# soc_debugss_secure register map
Vendor: Texas Instruments
Peripheral module from a debugger description file (folder CC35X1E).
Registers are 32-bit, read-only, reset 0x0 unless marked. A register's access mark holds for its fields unless they carry their own. Offsets are as the file gives them; lines under a group give offsets from that group; [hi:lo] are bit positions; {n}, {i} and the like mark numbered series; 'fields as' and 'values as' point back to an identical list; <NAME> marks a mode.

## soc_debugss_secure
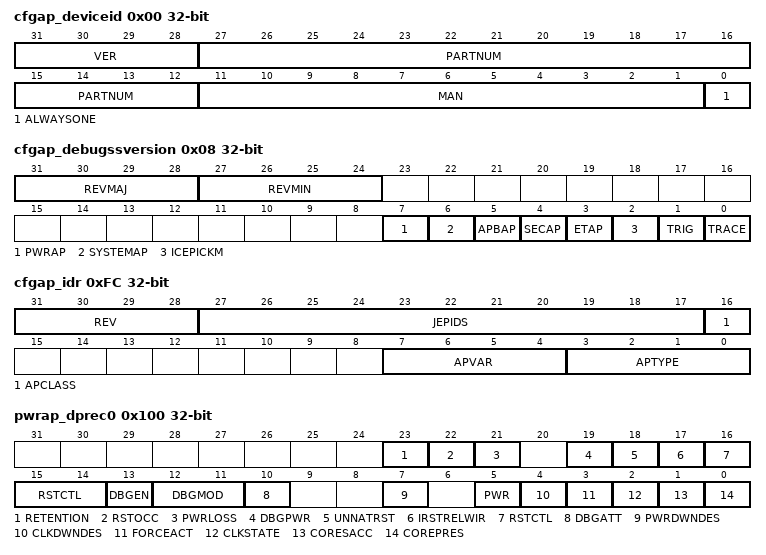
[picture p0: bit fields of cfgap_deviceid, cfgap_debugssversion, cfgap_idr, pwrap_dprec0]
0x00 cfgap_deviceid reset not defined — CFGAP Device ID. The device identification register allows the manufacturer, part number, and version of a component to be determined. This is the same 32-bit value obtained via the IDCODE instruction in the optional ICEPickM Scan module and is determined by tie-offs at DebugSS boundary.
  [31:28] VER — Revision of the device. This field should change each time that the logic or mask set of the device is revised.
  [27:12] PARTNUM — Identifies the part
  [11:1] MAN — TI's JEDEC bank and company code, which is 00000010111b
  [0] ALWAYSONE — The value 1 in bit 0 of a JTAG IDCODE means that a 32-bit scan register exists. This is replicated here for completeness.
0x04 cfgap_deviceusercode — CFGAP Device User Code. The Device Usercode register is used in conjunction with the Device Identification Register to provide extended device information. This is the same 32-bit value obtained via the USERCODE instruction in the optional ICEPickM Scan module and is determined by tie-offs at DebugSS boundary.
  [31:0] USERCODE — The Device Usercode register is used in conjunction with the Device Identification Register to provide extended device information. This is the same 32-bit value obtained via the USERCODE instruction in the optional ICEPickM Scan module and is determined by tie-offs at DebugSS boundary.
0x08 cfgap_debugssversion reset not defined — CFGAP DEBUGSS Version. The DebugSS Configuration Register provides information on the configuration of this particular instance of the subsystem.
  [31:28] REVMAJ — Indicates the major revision of this Subsystem instance.
  [27:24] REVMIN — Indicates the minor revision of this Subsystem instance. Currently 0000b
  [7] PWRAP — A value of '1' indicates this subsystem instance contains a Power-AP module
  [6] SYSTEMAP — A value of '1' indicates this subsystem instance contains an AHB-AP module for system bus mastering
  [5] APBAP — A value of '1' indicates this subsystem instance contains an ABP-AP for accessing system level debug components
  [4] SECAP — A value of '1' indicates this subsystem instance contains a Secure AP
  [3] ETAP — A value of '1' indicates this subsystem instance contains an EnergyTrace AP
  [2] ICEPICKM — A value of '1' indicates this subsystem instance contains an ICEPickM Scan module for extended scan support
  [1] TRIG — A value of '1' indicates this subsystem instance contains Cross Trigger submodule
  [0] TRACE — A value of '1' indicates this subsystem instance contains a Trace submodule
0x10 cfgap_bootdiag — CFGAP Boot Diag. This register provides feedback on the boot process
  [31:0] DIAGVAL — This register provides feedback on the boot process [3:0] PG_Version [5:3] Metal_Version [8:6] Memory Stacking [11:9] Package type [13:12] Temperature [17:14] Device PartNumber [18] Disable 5GHz [19] Disable 6GHz [20] Disable BLE [21] Disable BLE M0+ [22] Disable CAN FD [25:23] Boot ROM Version (FMU) [26] Launch pad Mode [28:27] SDIO Product ID [31:29] TI Fuse ROM Structure Version
0x14 cfgap_lifecyclestate — CFGAP Life-cycle. Indicates the current device lifecycle state
  [31:0] LCSVAL — Life cycle state [3:0] PG_Version [5:3] Metal_Version [8:6] Memory Stacking [11:9] Package type [13:12] Temperature [17:14] Device PartNumber [18] Disable 5GHz [19] Disable 6GHz [20] Disable BLE [21] Disable BLE M0+ [22] Disable CAN FD [25:23] Boot ROM Version (FMU) [26] Launch pad Mode [28:27] SDIO Product ID [31:29] TI Fuse ROM Structure Version
0x18 dft_en access per field — DFT Enable. This bit can be configured to enable multiplexing of JTAG signals on device pins.
  [0] EN rw — This bit can be configured to enable multiplexing of JTAG signals on device pins. Pin #2 --> TCK ;Pin #3 --> TMS ; Pin #10 --> TDI ; Pin #15 --> TDO. Refer to pinout_iomux.xls for more information.
0x1C rst_req access per field — Reset Request. This bit can be configured to request reset.
  [0] REQ wo — This bit can be configured to request device reset
0x28 cfgap_unique_deviceid_0 — CFGAP Unique Device 0. Used to provide a unique device ID/token for security authentication of tester and tools. Unique device ID is 64bit value and this register reads lower 32 bits.
  [31:0] VAL — Used to provide a unique divide ID/token for security authentication of tester and tools
0x2C cfgap_unique_deviceid_1 — CFGAP Unique Device 1. Used to provide a unique device ID/token for security authentication of tester and tools. Unique device ID is 64bit value and this register reads upper 32 bits.
  [31:0] VAL — Used to provide a unique devide ID/token for security authentication of tester and tools
0xFC cfgap_idr reset not defined — CFGAP Identification Register. AP Identification Register. The AP identification register allows tools to determine the manufacturer and the type of AP.
  [31:28] REV — Component Revision. Indicates the revision of this AP instance. Currently 0001b
  [27:17] JEPIDS — Manufacturer JEP106 ID. The concatenated JEP106 ID and continuation ID for TI. This is 00000010111b.
  [16] APCLASS — AP Class. 0 indicates that this AP is not a bridge to a memory interconnect (not a Memory Access Port).
  [7:4] APVAR — AP Variant. There is only one variant for this AP Type and it is 0.
  [3:0] APTYPE — The AP Type Register. TI Subsystem Config APs have a type of 0001b
0x100 pwrap_dprec0 access per field — Sub-Domain PREC Register This register provides an interface for debug tooling to obtain status and override the power, reset and execution state of debug targets in dynamically controlled sub-domains.
  [23] RETENTION ro — Used to indicate that the domain entered retention since the bit is cleared. Not supported in MX.
  [22] RSTOCC rw — Input from CPU-SS. Used by debug tools. A sticky bit Indicate that a reset to WSOC MCU has happened since last time tools checked. Cleared on write by the tool.
  [21] PWRLOSS rw — Input from PRCM. Used by debug tools. A sticky bit Indicate that a power loss to CORE has happened since last time tools checked. Cleared on write by the tool.
  [19] DBGPWR ro — Used to indicate power state of debug logic in the associated domain. 0 -> Debug logic is off. 1 -> Debug logic is powered.
  [18] UNNATRST ro — input from PRCM. "1" indicate that WSOC MCU (SYSRSTn) reset is extended.
  [17] IRSTRELWIR rw — Input from PRCM. "1" indicates WSOC MCU is in reset. Setting this bit shall release the extended SYSRSTn to WSOc MCU.
  [16:14] RSTCTL rw — Following are the field values with their description. 000 -> Normal Operation; 001 -> Wait in Reset (Reset Ext); 010 -> Block Reset; 100- > Reset Req.
  [13] DBGEN rw — Defines operating mode of debug logic in Cortex. Not used in MX.
  [12:11] DBGMOD rw — Used to define debug properties. Not used in MX.
  [10] DBGATT ro — Input from CPU-SS. "1" indicate that WSOC MCU is halted and in debug mode.
  [7] PWRDWNDES ro — Input from ELP. Indicates that CORE domain can be shutdown.
  [5] PWR ro — Input from PRCM. "1" indicates CORE domain is powered.
  [4] CLKDWNDES ro — "1" indicated that WSOC MCU is clocked artificially.
  [3] FORCEACT rw — Provides debug override of the default state of the CORE P.D power and clock.
  [2] CLKSTATE ro — Input from CPU-SS. "1" indicated that WSOC MCU is clocked by it's functional clock.
  [1] CORESACC ro — Input from DSSM. Indicate that WSOC MCU Power-AP overrides are writable.
  [0] COREPRES ro — 1 indicates that WSOC MCU is present in this Osprey device.
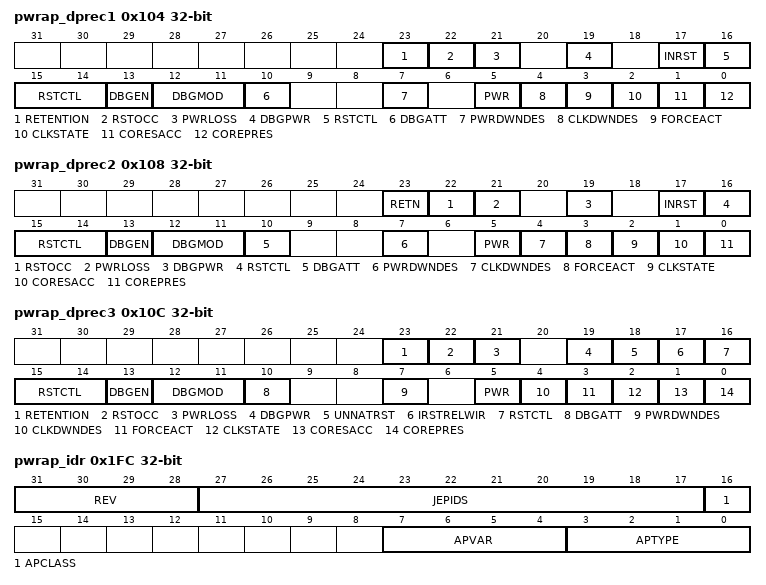
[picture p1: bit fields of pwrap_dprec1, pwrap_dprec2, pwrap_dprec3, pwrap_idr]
0x104 pwrap_dprec1 access per field — Sub-Domain PREC Register This register provides an interface for debug tooling to obtain status and override the power, reset and execution state of debug targets in dynamically controlled sub-domains.
  [23] RETENTION ro — Used to indicate that the domain entered retention since the bit is cleared. Not supported in MX.
  [22] RSTOCC rw — Input from CPU-SS. Used by debug tools. A sticky bit Indicate that a reset to WPHY MCU has happened since last time tools checked. Cleared on write by the tool.
  [21] PWRLOSS rw — Input from PRCM. Used by debug tools. A sticky bit Indicate that a power loss to CORE has happened since last time tools checked. Cleared on write by the tool.
  [19] DBGPWR ro — Used to indicate power state of debug logic in the associated domain. 0 -> Debug logic is off. 1 -> Debug logic is powered.
  [17] INRST ro — Input from PRCM. "1" indicates WPHY MCU is in reset.
  [16:14] RSTCTL rw — Following are the field values with their description. 000 -> Normal Operation; 001 -> Wait in Reset (Reset Ext); 010 -> Block Reset; 100- > Reset Req.
  [13] DBGEN rw — Defines operating mode of debug logic in Cortex. Not used in MX.
  [12:11] DBGMOD rw — Used to define debug properties. Not used in MX.
  [10] DBGATT ro — Input from CPU-SS. "1" indicate that WPHY MCU is halted and in debug mode.
  [7] PWRDWNDES ro — Input from ELP. Indicates that CORE domain can be shutdown.
  [5] PWR ro — Input from PRCM. "1" indicates CORE domain is powered.
  [4] CLKDWNDES ro — Input from ?. "1" indicated that WPHY MCU is clocked artificially.
  [3] FORCEACT rw — Provides debug override of the default state of the CORE P.D power and clock.
  [2] CLKSTATE ro — Input from CPU-SS. "1" indicated that WPHY MCU is clocked by it's functional clock.
  [1] CORESACC ro — Input from DSSM. Indicate that WSOC MCU, WPHY and LRF MCU (CORE domain cores) Power-AP overrides are writable.
  [0] COREPRES ro — 1 indicates that WPHY MCU is present in this Osprey device.
0x108 pwrap_dprec2 access per field — Sub-Domain PREC Register This register provides an interface for debug tooling to obtain status and override the power, reset and execution state of debug targets in dynamically controlled sub-domains.
  [23] RETN ro — Used to indicate that the domain entered retention since the bit is cleared. Not supported in MX.
  [22] RSTOCC rw — Input from CPU-SS. Used by debug tools. A sticky bit Indicate that a reset to LRF MCU has happened since last time tools checked. Cleared on write by the tool.
  [21] PWRLOSS rw — Input from PRCM. Used by debug tools. A sticky bit Indicate that a power loss to CORE has happened since last time tools checked. Cleared on write by the tool.
  [19] DBGPWR ro — Used to indicate power state of debug logic in the associated domain. 0 -> Debug logic is off. 1 -> Debug logic is powered.
  [17] INRST ro — Input from PRCM. "1" indicates LRF MCU is in reset.
  [16:14] RSTCTL rw — Following are the field values with their description. 000 -> Normal Operation; 001 -> Wait in Reset (Reset Ext); 010 -> Block Reset; 100- > Reset Req.
  [13] DBGEN rw — Defines operating mode of debug logic in Cortex. Not used in MX.
  [12:11] DBGMOD rw — Used to define debug properties. Not used in MX.
  [10] DBGATT ro — Input from CPU-SS. "1" indicate that LRF MCU is halted and in debug mode.
  [7] PWRDWNDES ro — Input from ELP. Indicates that CORE domain can be shutdown.
  [5] PWR ro — Input from PRCM. "1" indicates CORE domain is powered.
  [4] CLKDWNDES ro — Input from ?. "1" indicated that LRF MCU is clocked artificially.
  [3] FORCEACT rw — Provides debug override of the default state of the CORE P.D power and clock.
  [2] CLKSTATE ro — Input from CPU-SS. "1" indicated that LRF MCU is clocked by it's functional clock.
  [1] CORESACC ro — Input from DSSM. Indicate that WSOC MCU, WPHY and LRF MCU (CORE domain cores) Power-AP overrides are writable.
  [0] COREPRES ro — 1 indicates that LRF MCU is present in this Osprey device.
0x10C pwrap_dprec3 access per field — Sub-Domain PREC Register This register provides an interface for debug tooling to obtain status and override the power, reset and execution state of debug targets in dynamically controlled sub-domains.
  [23] RETENTION ro — Used to indicate that the domain entered retention since the bit is cleared. Not supported in MX.
  [22] RSTOCC rw — Input from CPU-SS. Used by debug tools. A sticky bit Indicate that a reset to APP MCU has happened since last time tools checked. Cleared on write by the tool.
  [21] PWRLOSS rw — Input from PRCM. Used by debug tools. A sticky bit Indicate that a power loss to HOST has happened since last time tools checked. Cleared on write by the tool.
  [19] DBGPWR ro — Used to indicate power state of debug logic in the associated domain. 0 -> Debug logic is off. 1 -> Debug logic is powered.
  [18] UNNATRST ro — input from PRCM. "1" indicate that APPCPU (SYSRSTn) reset is extended.
  [17] IRSTRELWIR ro — Input from PRCM. "1" indicates APP MCU is in reset.
  [16:14] RSTCTL rw — Following are the field values with their description. 000 -> Normal Operation; 001 -> Wait in Reset (Reset Ext); 010 -> Block Reset; 100- > Reset Req.
  [13] DBGEN rw — Defines operating mode of debug logic in Cortex. Not used in MX.
  [12:11] DBGMOD rw — Used to define debug properties. Not used in MX.
  [10] DBGATT ro — Input from CPU-SS. "1" indicate that APP MCU is halted and in debug mode.
  [7] PWRDWNDES ro — Input from ?. Indicates that HOST domain can be shutdown.
  [5] PWR ro — Input from PRCM. "1" indicates HOST domain is powered.
  [4] CLKDWNDES ro — Input from ?. "1" indicated that APP MCU is clocked artificially.
  [3] FORCEACT rw — Provides debug override of the default state of the HOST P.D power and clock.
  [2] CLKSTATE ro — Input from CPU-SS. "1" indicated that APP MCU is clocked by it's functional clock.
  [1] CORESACC ro — Input from DSSM. Indicate that HOST Power-AP overrides are writable.
  [0] COREPRES ro — 1 indicates that APP MCU is present in this Osprey device.
0x1FC pwrap_idr reset not defined — PWEAP Identification Register. The AP identification register allows tools to determine the manufacturer and the type of AP.
  [31:28] REV — Component Revision. Indicates the revision of this AP instance. Currently 0000b
  [27:17] JEPIDS — Manufacturer JEP106 ID. The concatenated JEP106 ID and continuation ID for TI. This is 00000010111b.
  [16] APCLASS — AP Class. 0 indicates that this is AP is not a bridge to a memory interconnect (not a Memory Access Port).
  [7:4] APVAR — AP Variant. There is only one variant for this AP Type and it is 0.
  [3:0] APTYPE — The AP Type Register. TI Subsystem Config APs have a type of 0001b
0x200 secap_txdata rw — Transmit Data Register. This register is used to pass data to the system security logic.
  [31:0] VAL
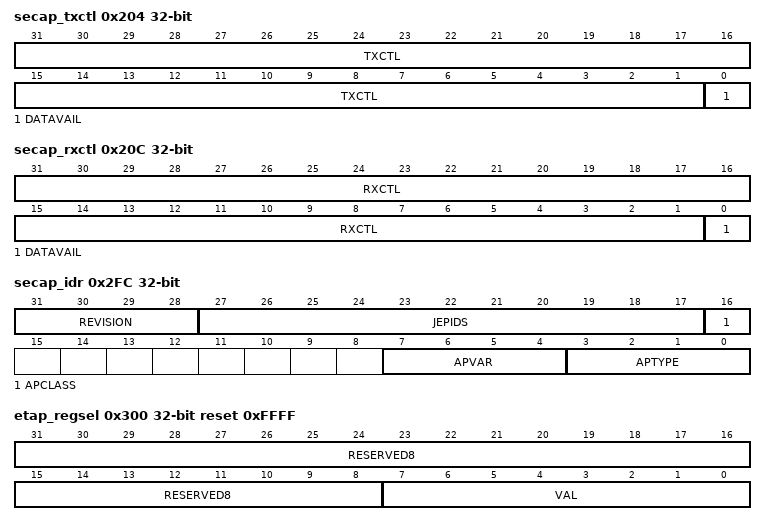
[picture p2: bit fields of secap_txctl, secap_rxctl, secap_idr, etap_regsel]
0x204 secap_txctl access per field — Transmit Control Register. This register provides the handshake for the TX Data Register and can also be used to pass control data to the system security logic.
  [31:1] TXCTL rw — Device specific control information from the system security logic
  [0] DATAVAIL ro — Transmit Data Available. Set automatically when the TX data Register is written Cleared automatically when the system debug logic indicates it has accepted the TX data
0x208 secap_rxdata — Receive Data Register. This register is used to pass data from the system security logic.
  [31:0] VAL
0x20C secap_rxctl access per field — Receive Control Register. This register provides the handshake for the RX Data Register and can also be used to pass control data from the system security logic.
  [31:1] RXCTL rw — Device specific control information from the system security logic
  [0] DATAVAIL ro — Set automatically when the system security logic indicates that RX Data Register is valid. Cleared automatically when the RX data Register is read.
0x2FC secap_idr reset not defined — AP Identification Register. The AP identification register allows tools to determine the manufacturer and the type of AP.
  [31:28] REVISION — Component Revision. Indicates the revision of this AP instance.
  [27:17] JEPIDS — Manufacturer JEP106 ID. The concatenated JEP106 ID and continuation ID for TI. This is 00000010111b.
  [16] APCLASS — AP Class. 0 indicates that this AP is not a bridge to a memory interconnect (not a Memory Access Port).
  [7:4] APVAR — AP Variant. There is only one variant for this AP Type and it is 0.
  [3:0] APTYPE — The AP Type Register.
0x300 etap_regsel access per field reset 0xFFFF — ETAP Register Selector. Has a bit associated with each 32-bit Status Bitfield in the status array. Bit 0 corresponds to Status Bitfield 0. At reset all available Status Bitfields are selected. After writing this bitfield STATREAD will return the value of the status bitfield with the lowest selected index.
  [31:8] RESERVED8 ro — Reads to this field return zero, writes to this field are ignored.
  [7:0] VAL rw — Has a bit associated with each 32-bit Status Bitfield in the status array. Bit 0 corresponds to Status Bitfield 0. At reset all available Status Bitfields are selected. After writing this bitfield [ETAPSTARD.*] will return the value of the status bitfield with the lowest selected index. Attempting to select an unimplemented register will not set the associated bit.
0x304 etap_capctrl reset not defined — ETAP Capability Control. This register can be used to read out the capability parameters of EnergyTrace and allows controlling the function.
  [7:0] NUMREGS — Indicates the number of available 32bit register containing EnergyTrace data. Actual registers is NUMREGS + 1.
0x308 etap_statread — ETAP Status Read. Returns the value of the EnergyTrace++ status bitfields. After writing the [ETAPSEL.*] bitfield, this register will return the value of the first available status bitfield. Subsequent reads will return the remaining bitfields as selected with [ETAPSEL.*].
  [31:0] FLAGS — Returns the value of the EnergyTrace++ status bitfields. After writing the [ETAPSEL.*] bitfield, this register will return the value of the first available status bitfield. Subsequent reads will return the remaining bitfields as selected with [ETAPSEL.*].
0x30C etap_dmnctrl access per field reset not defined — ETAP Domain Control. Controls which async domains are included in the async handshake sequence for data capture.
  [7:0] DMNINC rw — Each bit in this bitfield is associated with one of the 16 async domain controls (req/ack) supported by the ET-AP 0 = The domain is not included in the handshake request 1 = The domain is included in the handshake request Osprey MDB, all 8 ET status buses are synchronous, this register will read all zeroes and writes will be ignored. The mapping of domains to specific ET data sources is in device specific documentation
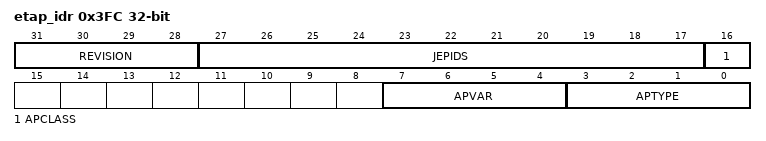
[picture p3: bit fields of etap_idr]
0x3FC etap_idr reset not defined — ETAP Identification Register. AP Identification Register. The AP identification register allows tools to determine the manufacturer and the type of AP.
  [31:28] REVISION — Component Revision. Indicates the revision of this AP instance. Currently 0000b
  [27:17] JEPIDS — Manufacturer JEP106 ID. The concatenated JEP106 ID and continuation ID for TI. This is 00000010111b.
  [16] APCLASS — AP Class. 0 indicates that this is AP is not a bridge to a memory interconnect (not a Memory Access Port).
  [7:4] APVAR — AP Variant. There is only one variant for this AP Type and it is 0.
  [3:0] APTYPE — The AP Type Register.
